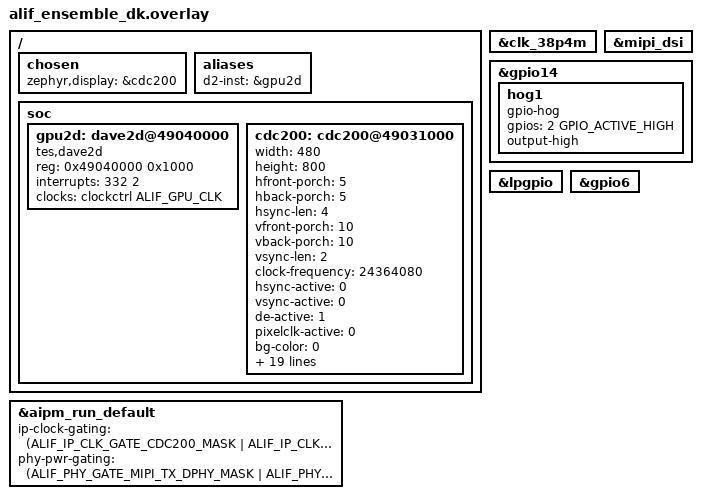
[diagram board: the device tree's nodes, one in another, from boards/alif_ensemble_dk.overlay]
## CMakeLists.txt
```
# Copyright (C) Alif Semiconductor - All Rights Reserved.
# Use, distribution and modification of this code is permitted under the
# terms stated in the Alif Semiconductor Software License Agreement
#
# You should have received a copy of the Alif Semiconductor Software
# License Agreement with this file. If not, please write to:
# contact@alifsemi.com, or visit: https://alifsemi.com/license
#

cmake_minimum_required(VERSION 3.20.0)

find_package(Zephyr REQUIRED HINTS $ENV{ZEPHYR_BASE})
project(lvgl_dave2d_benchmark)

set(LVGL_DIR ${ZEPHYR_LVGL_MODULE_DIR})

target_sources(app PRIVATE src/main.c)

# Shared demo entry helper (lv_demo_args_init) used by the LVGL demos; split out
# into its own translation unit in LVGL 9.5.0. Needed by any enabled demo, so
# gate on either the benchmark or the widgets demo being built.
if(CONFIG_LV_USE_DEMO_WIDGETS OR CONFIG_LV_USE_DEMO_BENCHMARK)
  target_sources(app PRIVATE ${LVGL_DIR}/demos/lv_demos.c)
endif()

target_include_directories(app PRIVATE ${LVGL_DIR}/demos/)

# LVGL's upstream D/AVE 2D draw unit pulls in
# "bsp_api.h". The include/ directory provides a compatibility shim that maps
# the TES D/AVE 2D driver headers. It must be visible to the LVGL module library
# build (not just the app), so it is added to the global include path.
zephyr_include_directories(include)

# The upstream draw unit gates its D-cache maintenance (clean/invalidate of the
# GPU source and destination buffers) behind the macros
# ARM_CORTEX_M55_M85 and BSP_CFG_DCACHE_ENABLED. The guarded code itself is
# portable (CMSIS SCB_* and the Alif d1_cacheblockflush() helper). The Alif
# Cortex-M55 runs with D-cache enabled and the GPU buffers live in cacheable
# SRAM, so this maintenance is required for CPU/GPU coherency. Define the macros
# for the whole build (the LVGL module needs them too, not just the app).
zephyr_compile_definitions(ARM_CORTEX_M55_M85=1 BSP_CFG_DCACHE_ENABLED=1)

# In DIRECT mode the LVGL VDBs are the scan-out framebuffers, so the CDC200
# driver's own statically allocated layer-1 framebuffer (768 KB of SRAM0) is
# never used after the first cdc200_swap_fb(). NO_RELOCATE_SRAM0 makes the
# driver skip that allocation and start scanning out from the start of SRAM0,
# which is where lvgl_sram.ld places the VDBs; main.c points it at the active
# VDB before LVGL renders its first frame.
zephyr_compile_definitions(NO_RELOCATE_SRAM0)

# lv_demo_benchmark cycles through the widgets demo scenes, so both the
# benchmark and widgets demo sources are required.
target_sources_ifdef(CONFIG_LV_USE_DEMO_BENCHMARK app PRIVATE
    ${LVGL_DIR}/demos/benchmark/lv_demo_benchmark.c
    ${LVGL_DIR}/demos/benchmark/assets/img_benchmark_avatar.c
    ${LVGL_DIR}/demos/benchmark/assets/img_benchmark_lvgl_logo_argb.c
    ${LVGL_DIR}/demos/benchmark/assets/img_benchmark_lvgl_logo_rgb.c
    ${LVGL_DIR}/demos/benchmark/assets/lv_font_benchmark_montserrat_14_aligned.c
    ${LVGL_DIR}/demos/benchmark/assets/lv_font_benchmark_montserrat_20_aligned.c
    ${LVGL_DIR}/demos/benchmark/assets/lv_font_benchmark_montserrat_24_aligned.c
    ${LVGL_DIR}/demos/benchmark/assets/lv_font_benchmark_montserrat_26_aligned.c
)

target_sources_ifdef(CONFIG_LV_USE_DEMO_WIDGETS app PRIVATE
    ${LVGL_DIR}/demos/widgets/lv_demo_widgets.c
    ${LVGL_DIR}/demos/widgets/lv_demo_widgets_analytics.c
    ${LVGL_DIR}/demos/widgets/lv_demo_widgets_components.c
    ${LVGL_DIR}/demos/widgets/lv_demo_widgets_profile.c
    ${LVGL_DIR}/demos/widgets/lv_demo_widgets_shop.c
    ${LVGL_DIR}/demos/widgets/assets/img_clothes.c
    ${LVGL_DIR}/demos/widgets/assets/img_demo_widgets_avatar.c
    ${LVGL_DIR}/demos/widgets/assets/img_demo_widgets_needle.c
    ${LVGL_DIR}/demos/widgets/assets/img_lvgl_logo.c
)

# The LVGL rendering buffers (.lvgl_buf) and memory pool (.lvgl_heap) are
# rendered into by the D/AVE 2D GPU as a bus master, so relocate them into
# globally addressable SRAM0. In DIRECT mode these full-screen VDBs also
# serve as the CDC200 scan-out framebuffers (zero-copy page-flip).
zephyr_linker_sources_ifdef(CONFIG_LV_Z_VDB_CUSTOM_SECTION
    SECTIONS lvgl_sram.ld)
```

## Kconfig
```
# Copyright (C) Alif Semiconductor - All Rights Reserved.
# Use, distribution and modification of this code is permitted under the
# terms stated in the Alif Semiconductor Software License Agreement
#
# You should have received a copy of the Alif Semiconductor Software
# License Agreement with this file. If not, please write to:
# contact@alifsemi.com, or visit: https://alifsemi.com/license
#

mainmenu "LVGL D/AVE 2D benchmark"

config APP_DAVE2D_HEAP_SIZE
	int "D/AVE 2D heap size in bytes"
	default 65536
	help
	  Size of the D/AVE 2D heap in SRAM1. The LVGL draw unit needs about
	  24 KB (measured with APP_DAVE2D_HEAP_HWM). Must be a multiple of
	  CONFIG_D0_FIXED_RANGE_ALIGNMENT.

config APP_DAVE2D_HEAP_HWM
	bool "Report the D/AVE 2D heap high-water mark"
	help
	  Fill the D/AVE 2D heap with a known pattern before the heap manager
	  is initialised and, when the benchmark finishes, scan it for the
	  highest byte that was ever written. The result is logged as the
	  peak heap extent used and can be used to size APP_DAVE2D_HEAP_SIZE.

config APP_LVGL_HEAP_STATS
	bool "Report LVGL memory pool and main stack usage"
	select SYS_HEAP_RUNTIME_STATS
	select INIT_STACKS
	select THREAD_STACK_INFO
	help
	  Log the current and peak usage of the LVGL memory pool
	  (CONFIG_LV_Z_MEM_POOL_SIZE) and the peak usage of the main thread
	  stack, which runs lv_timer_handler(), when the benchmark finishes.
	  Can be used to size the pool and CONFIG_MAIN_STACK_SIZE.

source "Kconfig.zephyr"
```

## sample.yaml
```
sample:
  name: LVGL D/AVE 2D Benchmark
  description: >
    LVGL lv_demo_benchmark rendered through the D/AVE 2D GPU on the
    Alif Ensemble E8 DevKit MW405 display.
common:
  modules:
    - lvgl
  tags:
    - display
    - lvgl
    - gui
    - dave2d
    - gpu2d
  harness: console
  harness_config:
    type: one_line
    regex:
      - "All scenes avg"
  depends_on: display
tests:
  sample.modules.lvgl.benchmark.dave2d:
    platform_allow:
      - alif_e8_dk/ae822fa0e5597xx0/rtss_he
      - alif_e8_dk/ae822fa0e5597xx0/rtss_hp
    integration_platforms:
      - alif_e8_dk/ae822fa0e5597xx0/rtss_he
```

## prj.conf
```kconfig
# Copyright (C) Alif Semiconductor - All Rights Reserved.
# Use, distribution and modification of this code is permitted under the
# terms stated in the Alif Semiconductor Software License Agreement
#
# You should have received a copy of the Alif Semiconductor Software
# License Agreement with this file. If not, please write to:
# contact@alifsemi.com, or visit: https://alifsemi.com/license
#

# Display pipeline: CDC200 controller + MIPI-DSI host + MW405 panel.
CONFIG_DISPLAY=y
CONFIG_MIPI_DSI=y

# LVGL and the benchmark demo (cycles through the widgets demo scenes).
CONFIG_LVGL=y
CONFIG_LV_USE_DEMO_BENCHMARK=y
CONFIG_LV_USE_DEMO_WIDGETS=y

# Refresh at ~60 FPS. The LVGL default is 33 ms (~30 FPS), which caps the
# benchmark's reported FPS at 30 regardless of how fast the D/AVE 2D GPU renders.
CONFIG_LV_DEF_REFR_PERIOD=16

# Performance monitor (sysmon). The benchmark reports per-scene FPS/CPU through
# it; without it the on-screen title shows "LV_USE_PERF_MONITOR is not enabled"
# and the summary table reports "N/A" for every scene.
CONFIG_LV_USE_SYSMON=y
CONFIG_LV_USE_PERF_MONITOR=y
# Print the benchmark's CSV summary to the serial console. The demo emits it via
# lv_log() at USER level; route it through LVGL's logging (the Zephyr glue maps
# USER -> LOG_INF on the "lvgl" module, which needs CONFIG_LV_Z_LOG_LEVEL=3/INFO,
# selected by the USER level choice below).
# (CONFIG_LV_USE_PERF_MONITOR_LOG_MODE would additionally stream the per-refresh
# FPS/CPU line to the log; left off so only the summary is printed.)
CONFIG_LV_USE_LOG=y
CONFIG_LV_LOG_LEVEL_USER=y

CONFIG_LV_USE_FONT_COMPRESSED=y
CONFIG_LV_FONT_MONTSERRAT_12=y
CONFIG_LV_FONT_MONTSERRAT_14=y
CONFIG_LV_FONT_MONTSERRAT_16=y
CONFIG_LV_FONT_MONTSERRAT_24=y
CONFIG_LV_FONT_MONTSERRAT_28=y

# LVGL memory pool. Every lv_malloc() comes from here: widget objects, the
# simple-layer scratch buffers, and the transient A8 glyph bitmap buffers that
# lv_draw_label allocates per letter. The benchmark peaks at about 107 KB
# (measured with CONFIG_APP_LVGL_HEAP_STATS); 256 KB leaves room for heap
# overhead and fragmentation. Running out is fatal: LV_ASSERT_MALLOC is a no-op
# without CONFIG_ASSERT, so a failed allocation is dereferenced as NULL (MPU
# fault). The pool lives in .lvgl_heap (SRAM0).
CONFIG_LV_Z_MEM_POOL_SIZE=262144
# The pool is a Zephyr sys_heap. Because the zephyr,sram region (DTCM) is only
# 256 KB, the heap type defaults to SYS_HEAP_SMALL_ONLY, which supports heaps of
# at most 262136 bytes - larger heaps get their chunk sizes truncated (the size
# check is an assert, compiled out unless CONFIG_ASSERT=y). The 256 KB pool is
# 8 bytes over that limit, so select the auto-sized heap.
CONFIG_SYS_HEAP_AUTO=y

# Simple-layer scratch buffer used to composite widgets with style_opa < 255 or a
# non-normal blend mode (the benchmark's "Containers with opa_layer" scene). The
# 24 KB default composites such layers in many small chunks and emits the runtime
# note "LV_DRAW_LAYER_SIMPLE_BUF_SIZE is small making opa_layered slow" (wants
# >= 1/20 of the 480x800x2 screen, ~38 KB). 48 KB clears the note.
#
# Enlarging this used to crash the D/AVE 2D GPU, but that was a symptom, not the
# cause: the real bug was a deferred-render buffer-lifetime race in the dave2d
# unit (fixed in the lvgl module, run-to-completion + clip clamp). The bigger
# buffer merely made taller chunks that hit the race more often. With the module
# fix in place the size is safe again.
CONFIG_LV_DRAW_LAYER_SIMPLE_BUF_SIZE=49152

# Double-buffered, statically allocated rendering buffers. The custom sections
# (.lvgl_buf / .lvgl_heap) are relocated to globally-addressable SRAM0 by
# lvgl_sram.ld so the D/AVE 2D GPU can render into them and the VDBs can also
# serve as the CDC200 scan-out framebuffers (DIRECT mode zero-copy page-flip).
CONFIG_LV_Z_BUFFER_ALLOC_STATIC=y
CONFIG_LV_Z_DOUBLE_VDB=y
CONFIG_LV_Z_VDB_CUSTOM_SECTION=y
CONFIG_LV_Z_MEMORY_POOL_CUSTOM_SECTION=y

# Size the VDBs for the RGB565 panel (16 bpp / 2 bytes per pixel). The Zephyr
# LVGL Kconfig has an unconditional "default 32" listed before the
# "default 16 if LV_COLOR_DEPTH_16" entry, so the bits-per-pixel must be pinned
# explicitly - otherwise the buffers would be allocated at 32 bpp (twice the
# size actually needed for RGB565).
CONFIG_LV_Z_BITS_PER_PIXEL=16

# DIRECT-mode rendering: two full-screen VDBs in SRAM0 ARE the scan-out
# framebuffers. The GPU renders directly into the back buffer while CDC200
# scans out the front buffer; main.c page-flips via cdc200_swap_fb() at
# vsync, so no CPU memcpy is needed.
CONFIG_LV_Z_VDB_SIZE=100
#CONFIG_LV_Z_FLUSH_THREAD=y

# Offload LVGL rendering to the D/AVE 2D GPU.
CONFIG_DAVE2D=y
CONFIG_LV_USE_DRAW_DAVE2D=y

# Build for speed (-O2) instead of the default size optimization (-Os). This
# speeds up all CPU-side work: draw-list building, the GPU dispatch path and the
# software fallback paths. There is ample MRAM headroom for the larger code.
CONFIG_SPEED_OPTIMIZATIONS=y

# Use the Cortex-M55 Helium (MVE) software-render backend for the draw operations
# the D/AVE 2D unit cannot offload (some blends/conversions), instead of scalar C.
CONFIG_LV_DRAW_SW_ASM_HELIUM=y

CONFIG_MAIN_STACK_SIZE=8192

CONFIG_LOG=y
# Use immediate logging so the CSV summary (a burst of ~18 lines emitted
# back-to-back) is captured in full. With deferred logging the small log ring
# buffer can overflow and drop summary lines before the lower-priority log thread
# drains it.
CONFIG_LOG_MODE_IMMEDIATE=y

# In DIRECT mode the LVGL VDBs ARE the scan-out framebuffers (both in SRAM0),
# so no separate CDC200 framebuffer is needed. Drop CONFIG_FB_USES_DTCM_REGION
# and the non-secure DTCM window.
#CONFIG_FB_USES_DTCM_REGION=y

CONFIG_LV_COLOR_DEPTH_16=y
```

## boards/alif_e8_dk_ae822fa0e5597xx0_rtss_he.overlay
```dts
/*
 * SPDX-FileCopyrightText: Copyright Alif Semiconductor
 * SPDX-License-Identifier: Apache-2.0
 */
#include "alif_ensemble_dk.overlay"
```

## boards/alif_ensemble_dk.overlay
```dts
/* Copyright (C) Alif Semiconductor - All Rights Reserved.
 * Use, distribution and modification of this code is permitted under the
 * terms stated in the Alif Semiconductor Software License Agreement
 *
 * You should have received a copy of the Alif Semiconductor Software
 * License Agreement with this file. If not, please write to:
 * contact@alifsemi.com, or visit: https://alifsemi.com/license
 *
 */

#include <zephyr/dt-bindings/clock/alif_ensemble_clocks.h>
#include <dt-bindings/misc/alif_aipm_ensemble_gen2.h>

/ {
	chosen {
		zephyr,display = &cdc200;
	};

	aliases {
		/* Used by the D/AVE 2D (d1) layer to locate the GPU node. */
		d2-inst = &gpu2d;
	};

	soc {
		gpu2d: dave2d@49040000 {
			compatible = "tes,dave2d";
			reg = <0x49040000 0x1000>;
			interrupts = <332 2>;
			clocks = <&clockctrl ALIF_GPU_CLK>;
		};

		/* Override the placeholder CDC200 timings for the 480x800 MW405 panel. */
		cdc200: cdc200@49031000 {
			width = <480>;
			height = <800>;
			hfront-porch = <5>;
			hback-porch = <5>;
			hsync-len = <4>;
			vfront-porch = <10>;
			vback-porch = <10>;
			vsync-len = <2>;
			clock-frequency = <24364080>;
			hsync-active = <0>;
			vsync-active = <0>;
			de-active = <1>;
			pixelclk-active = <0>;
			bg-color = <0>;
			enable-l1 = <1>;
			pixel-fmt-l1 = "rgb-565";
			def-back-color-l1 = <0>;
			win-x0-l1 = <0>;
			win-y0-l1 = <0>;
			win-x1-l1 = <480>;
			win-y1-l1 = <800>;
			blend-factor1-l1 = <4>;
			blend-factor2-l1 = <5>;
			const-alpha-l1 = <0xff>;
			enable-l2 = <0>;
			pixel-fmt-l2 = "undefined";
			win-x0-l2 = <0>;
			win-y0-l2 = <0>;
			win-x1-l2 = <0>;
			win-y1-l2 = <0>;
			blend-factor1-l2 = <6>;
			blend-factor2-l2 = <7>;
			const-alpha-l2 = <0xff>;
		};
	};
};

&aipm_run_default {
	ip-clock-gating = <(ALIF_IP_CLK_GATE_CDC200_MASK |
			    ALIF_IP_CLK_GATE_MIPI_DSI_MASK |
			    ALIF_IP_CLK_GATE_GPU_MASK)>;
	phy-pwr-gating  = <(ALIF_PHY_GATE_MIPI_TX_DPHY_MASK |
			    ALIF_PHY_GATE_MIPI_RX_DPHY_MASK |
			    ALIF_PHY_GATE_MIPI_PLL_DPHY_MASK |
			    ALIF_PHY_GATE_LDO_MASK)>;
};

&clk_38p4m {
	status = "okay";
};

&mipi_dsi {
	status = "okay";
};

/* GPIO controller for the MIPI camera/display mux (cam-disp-mux-gpios on the DSI
 * host). The application drives it to route the MIPI lanes to the panel.
 */
&gpio14 {
	status = "okay";

	hog1 {
		gpio-hog;
		gpios = <2 GPIO_ACTIVE_HIGH>;
		output-high;
	};
};

/* GPIO controllers used by the MW405 panel (reset on lpgpio, backlight on gpio6). */
&lpgpio {
	status = "okay";
};

&gpio6 {
	status = "okay";
};

/*
 * Non-secure DTCM window: not needed in DIRECT mode (the full-screen LVGL VDBs
 * in SRAM0 serve as both the GPU render targets and the CDC200 scan-out
 * framebuffers). Leave the ns node disabled (SoC default).
 */
```

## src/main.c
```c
/* Copyright (C) Alif Semiconductor - All Rights Reserved.
 * Use, distribution and modification of this code is permitted under the
 * terms stated in the Alif Semiconductor Software License Agreement
 *
 * You should have received a copy of the Alif Semiconductor Software
 * License Agreement with this file. If not, please write to:
 * contact@alifsemi.com, or visit: https://alifsemi.com/license
 *
 */

#include <zephyr/kernel.h>
#include <zephyr/init.h>
#include <zephyr/device.h>
#include <zephyr/drivers/clock_control.h>
#include <zephyr/drivers/display.h>
#include <zephyr/drivers/display/cdc200.h>
#if defined(CONFIG_MIPI_DSI)
#include <zephyr/drivers/mipi_dsi/dsi_dw.h>
#endif
#include <zephyr/cache.h>
#include <zephyr/linker/section_tags.h>
#include <zephyr/logging/log.h>
#include <se_service.h>
#include <soc_common.h>

#include <lvgl.h>
#include <lv_demos.h>

#include <dave_d0lib.h>

#if defined(CONFIG_APP_LVGL_HEAP_STATS)
#include <lvgl_mem.h>
#endif

LOG_MODULE_REGISTER(app, CONFIG_LOG_DEFAULT_LEVEL);

#if DT_NODE_HAS_STATUS(DT_ALIAS(panel), okay)
static int display_panel_on(void)
{
	const struct device *panel_dev = DEVICE_DT_GET(DT_ALIAS(panel));
	int ret;

	if (!device_is_ready(panel_dev)) {
		LOG_ERR("Display panel device not ready");
		return -ENODEV;
	}

	ret = display_blanking_off(panel_dev);
	if (ret) {
		LOG_ERR("Failed to turn display panel on (%d)", ret);
	}

	return ret;
}
#endif

/*
 * D/AVE 2D working memory (display lists, render buffers, ...). The LVGL D/AVE 2D
 * draw unit allocates from this heap inside lv_draw_dave2d_init(), which runs as
 * part of lv_init(). Zephyr's LVGL glue calls lv_init() automatically from a
 * SYS_INIT() hook at the APPLICATION init level, so the heap must already be
 * initialised by then - hence the POST_KERNEL SYS_INIT() below, which always
 * runs before any APPLICATION-level hook.
 *
 * The heap lives in SRAM1, and the LVGL rendering buffers + memory pool live in
 * SRAM0 (see lvgl_sram.ld) - both globally addressable, so the GPU can reach
 * them. In DIRECT mode the full-screen VDBs in SRAM0 double as the CDC200
 * scan-out framebuffers (zero-copy page-flip via cdc200_swap_fb).
 */
#define DAVE2D_HEAP_SIZE CONFIG_APP_DAVE2D_HEAP_SIZE
BUILD_ASSERT(DAVE2D_HEAP_SIZE % CONFIG_D0_FIXED_RANGE_ALIGNMENT == 0,
	     "D/AVE 2D heap size must be a multiple of the d0 allocator alignment");
static uint8_t __alif_sram1_section
	__aligned(CONFIG_D0_FIXED_RANGE_ALIGNMENT) dave2d_heap[DAVE2D_HEAP_SIZE];

#if defined(CONFIG_APP_DAVE2D_HEAP_HWM)
/*
 * The D/AVE 2D fixed-range allocator is first-fit from the bottom of the heap
 * and writes a block header right after every allocation it splits off, so the
 * highest byte that no longer holds the fill pattern marks the peak extent.
 */
#define DAVE2D_HEAP_FILL 0xA5A5A5A5U

static uint32_t dave2d_heap_hwm(void)
{
	const uint32_t *words = (const uint32_t *)dave2d_heap;
	size_t i = DAVE2D_HEAP_SIZE / sizeof(uint32_t);

	while (i > 0 && words[i - 1] == DAVE2D_HEAP_FILL) {
		i--;
	}

	return i * sizeof(uint32_t);
}
#endif

#if defined(CONFIG_APP_DAVE2D_HEAP_HWM) || defined(CONFIG_APP_LVGL_HEAP_STATS)
static void benchmark_end_cb(const lv_demo_benchmark_summary_t *summary)
{
#if defined(CONFIG_APP_DAVE2D_HEAP_HWM)
	uint32_t hwm = dave2d_heap_hwm();
#endif
#if defined(CONFIG_APP_LVGL_HEAP_STATS)
	struct sys_memory_stats stats;
	size_t stack_size = k_current_get()->stack_info.size;
	size_t stack_unused = 0;

	lvgl_heap_stats(&stats);
	(void)k_thread_stack_space_get(k_current_get(), &stack_unused);
#endif

	lv_demo_benchmark_summary_display(summary);

#if defined(CONFIG_APP_DAVE2D_HEAP_HWM)
	LOG_INF("D/AVE 2D heap high-water mark: %u of %u bytes (%u%%)", (unsigned int)hwm,
		(unsigned int)DAVE2D_HEAP_SIZE, (unsigned int)((hwm * 100U) / DAVE2D_HEAP_SIZE));
#endif
#if defined(CONFIG_APP_LVGL_HEAP_STATS)
	LOG_INF("LVGL pool: %u allocated, %u peak of %u bytes (peak %u%%)",
		(unsigned int)stats.allocated_bytes, (unsigned int)stats.max_allocated_bytes,
		(unsigned int)CONFIG_LV_Z_MEM_POOL_SIZE,
		(unsigned int)((stats.max_allocated_bytes * 100U) / CONFIG_LV_Z_MEM_POOL_SIZE));
	LOG_INF("Main stack: %u peak of %u bytes (%u%%)", (unsigned int)(stack_size - stack_unused),
		(unsigned int)stack_size,
		(unsigned int)(((stack_size - stack_unused) * 100U) / stack_size));
#endif
}
#endif

static int dave2d_heap_init(void)
{
#if defined(CONFIG_APP_DAVE2D_HEAP_HWM)
	for (size_t i = 0; i < DAVE2D_HEAP_SIZE / sizeof(uint32_t); i++) {
		((uint32_t *)dave2d_heap)[i] = DAVE2D_HEAP_FILL;
	}
#endif

	if (!d0_initheapmanager(dave2d_heap, sizeof(dave2d_heap), d0_mm_fixed_range,
				NULL, 0, 0, 0, d0_ma_unified)) {
		LOG_ERR("Failed to initialise the D/AVE 2D heap manager");
		return -ENOMEM;
	}

	return 0;
}
SYS_INIT(dave2d_heap_init, POST_KERNEL, CONFIG_KERNEL_INIT_PRIORITY_DEFAULT);

/*
 * DIRECT-mode flush callback with vsync synchronization. In DIRECT mode the
 * two full-screen LVGL VDBs ARE the scan-out framebuffers (both in SRAM0).
 * The GPU renders directly into the back buffer, and this flush callback
 * page-flips via cdc200_swap_fb() then waits for the CDC200 LINE IRQ to
 * actually process the swap. This ensures:
 *  - No tearing (buffer swap happens at vblank)
 *  - Smooth frame pacing (naturally locked to display refresh)
 *  - LVGL doesn't touch the new back buffer until the old front is released
 */
static void direct_flush_cb(lv_display_t *disp, const lv_area_t *area,
			     uint8_t *px_map)
{
	const struct device *dev = lv_display_get_user_data(disp);

	if (lv_display_flush_is_last(disp)) {
		uint32_t h = lv_display_get_vertical_resolution(disp);
		uint32_t w = lv_display_get_horizontal_resolution(disp);
		uint32_t stride = w * (LV_COLOR_DEPTH / 8);

		sys_cache_data_flush_range(px_map, stride * h);

		struct cdc200_fb_desc fb = {
			.fb_addr = px_map,
			.fb_size = stride * h,
		};

		cdc200_swap_fb(dev, 0, &fb);

		/* Block until the CDC200 ISR processes the swap at vblank. */
		cdc200_wait_vsync(dev, K_MSEC(50));
	}

	lv_display_flush_ready(disp);
}

/*
 * Set up DIRECT-mode rendering. Override the LVGL glue's default PARTIAL mode
 * flush with a zero-copy page-flip callback. The CDC200 must be pointed at one
 * of the VDBs initially; the first swap_fb call inside the flush callback
 * handles the transition.
 */
static void setup_direct_mode(const struct device *display_dev,
			       lv_display_t *disp)
{
	lv_display_set_render_mode(disp, LV_DISPLAY_RENDER_MODE_DIRECT);
	lv_display_set_flush_cb(disp, direct_flush_cb);
	lv_display_set_user_data(disp, (void *)display_dev);

	/*
	 * Point CDC200 at the first VDB so it has a valid scan-out address
	 * before LVGL renders its first frame.
	 */
	lv_draw_buf_t *buf0 = lv_display_get_buf_active(disp);

	if (buf0) {
		uint32_t h = lv_display_get_vertical_resolution(disp);
		uint32_t w = lv_display_get_horizontal_resolution(disp);
		struct cdc200_fb_desc fb = {
			.fb_addr = buf0->data,
			.fb_size = w * (LV_COLOR_DEPTH / 8) * h,
		};

		cdc200_swap_fb(display_dev, 0, &fb);
	}
}

int main(void)
{
	const struct device *display_dev = DEVICE_DT_GET(DT_CHOSEN(zephyr_display));

	if (!device_is_ready(display_dev)) {
		LOG_ERR("Display device not ready");
		return 0;
	}

#if defined(CONFIG_MIPI_DSI)
	{
		const struct device *dsi = DEVICE_DT_GET(DT_NODELABEL(mipi_dsi));
		int ret;

		if (!device_is_ready(dsi)) {
			LOG_ERR("MIPI-DSI host not ready");
			return 0;
		}

		/*
		 * The panel is initialised over the DSI link in command mode. Switch
		 * the host to video mode so the CDC200 framebuffer is actually
		 * streamed to the panel; without this the screen stays black even
		 * though the panel configured successfully.
		 */
		ret = dsi_dw_set_mode(dsi, DSI_DW_VIDEO_MODE);
		if (ret) {
			LOG_ERR("Failed to set DSI video mode (%d)", ret);
			return 0;
		}
	}
#endif

#if DT_NODE_HAS_STATUS(DT_ALIAS(panel), okay)
	if (display_panel_on()) {
		return 0;
	}
#endif

	/*
	 * The CDC200 controller is not started by its own driver init, and the
	 * generic display_blanking_off() API the LVGL glue calls is a no-op for
	 * it (returns -ENOTSUP). Start the scan-out engine explicitly here, or the
	 * panel stays dark even though the MIPI-DSI link and backlight are up.
	 */
	cdc200_set_enable(display_dev, true);

	/*
	 * Switch to DIRECT-mode: GPU renders into full-screen VDBs in SRAM0,
	 * flush callback page-flips via cdc200_swap_fb() at each vblank.
	 */
	lv_display_t *disp = lv_display_get_default();

	setup_direct_mode(display_dev, disp);

#if defined(CONFIG_APP_DAVE2D_HEAP_HWM) || defined(CONFIG_APP_LVGL_HEAP_STATS)
	lv_demo_benchmark_set_end_cb(benchmark_end_cb);
#endif
	lv_demo_benchmark();

	while (1) {
		uint32_t sleep_ms = lv_timer_handler();

		k_msleep(MIN(sleep_ms, INT32_MAX));
	}

	return 0;
}
```

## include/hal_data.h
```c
/* Copyright (C) Alif Semiconductor - All Rights Reserved.
 * Use, distribution and modification of this code is permitted under the
 * terms stated in the Alif Semiconductor Software License Agreement
 *
 * You should have received a copy of the Alif Semiconductor Software
 * License Agreement with this file. If not, please write to:
 * contact@alifsemi.com, or visit: https://alifsemi.com/license
 *
 */

#ifndef HAL_DATA_H
#define HAL_DATA_H

/*
 * Compatibility shim for LVGL's D/AVE 2D draw unit.
 *
 * The upstream D/AVE 2D draw unit transitively provides the driver
 * and the BSP cache configuration. This file is required to provide
 * a minimal stand-in for the D/AVE 2D driver and BSP cache
 * configuration, so that the D/AVE 2D draw unit can be used on Alif.
 */
#include <cmsis_core.h>

#include <dave_driver.h>
#include <dave_d0lib.h>

/*
 * lv_draw_dave2d_cf_fb_get() determines the D/AVE 2D framebuffer mode
 * from the display driver configuration (g_display0_cfg). On Alif the
 * LVGL framebuffer always matches the configured LVGL colour depth,
 * so we provide a minimal stand-in that reports that fixed format.
 */
typedef enum {
	DISPLAY_IN_FORMAT_16BITS_RGB565 = 0,
	DISPLAY_IN_FORMAT_32BITS_ARGB8888,
	DISPLAY_IN_FORMAT_32BITS_RGB888,
	DISPLAY_IN_FORMAT_16BITS_ARGB4444,
	DISPLAY_IN_FORMAT_16BITS_ARGB1555,
	DISPLAY_IN_FORMAT_CLUT8,
	DISPLAY_IN_FORMAT_CLUT4,
	DISPLAY_IN_FORMAT_CLUT1,
} display_in_format_t;

typedef struct {
	display_in_format_t format;
} display_input_cfg_t;

typedef struct {
	const display_input_cfg_t *input;
} display_cfg_t;

static const display_input_cfg_t _alif_dave2d_fb_input = {
#if LV_COLOR_DEPTH == 32
	.format = DISPLAY_IN_FORMAT_32BITS_ARGB8888,
#else
	.format = DISPLAY_IN_FORMAT_16BITS_RGB565,
#endif
};

static const display_cfg_t g_display0_cfg = {
	.input = &_alif_dave2d_fb_input,
};

#endif /* HAL_DATA_H */
```
